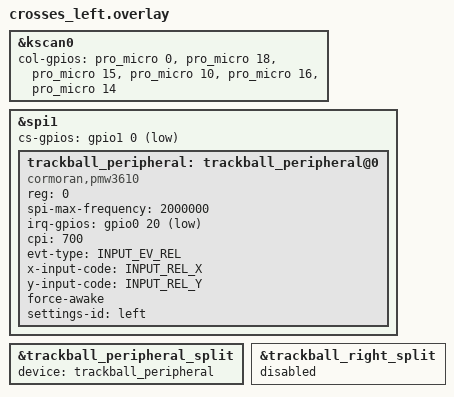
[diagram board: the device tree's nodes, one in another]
/*
 * Copyright (c) 2025 Vincent Franco
 * SPDX-License-Identifier: MIT
 */

#include "crosses.dtsi"
#include "split_input_common.dtsi"
#include <zephyr/dt-bindings/input/input-event-codes.h>

&kscan0 {
  col-gpios
    = <&pro_micro 0 GPIO_ACTIVE_HIGH>
    , <&pro_micro 18 GPIO_ACTIVE_HIGH>
    , <&pro_micro 15 GPIO_ACTIVE_HIGH>
    , <&pro_micro 10 GPIO_ACTIVE_HIGH>
    , <&pro_micro 16 GPIO_ACTIVE_HIGH>
    , <&pro_micro 14 GPIO_ACTIVE_HIGH>
    ;
};

&spi1 {
  cs-gpios = <&gpio1 0 GPIO_ACTIVE_LOW>;

  trackball_peripheral: trackball_peripheral@0 {
    status = "okay";
    compatible = "cormoran,pmw3610";
    reg = <0>;
    spi-max-frequency = <2000000>;
    irq-gpios = <&gpio0 20 (GPIO_ACTIVE_LOW | GPIO_PULL_UP)>;
    cpi = <700>;
    evt-type = <INPUT_EV_REL>;
    x-input-code = <INPUT_REL_X>;
    y-input-code = <INPUT_REL_Y>;
    force-awake;
    settings-id = "left";
  };
};

// Assign physical device to left split node; processors defined in split_input_common.dtsi
&trackball_peripheral_split {
  device = <&trackball_peripheral>;
};

// Right trackball split not used on left half
&trackball_right_split {
  status = "disabled";
};
